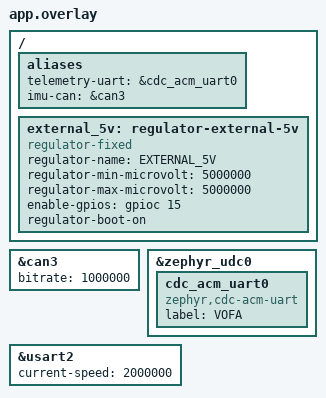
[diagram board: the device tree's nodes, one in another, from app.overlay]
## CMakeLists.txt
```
cmake_minimum_required(VERSION 3.20.0)
find_package(Zephyr REQUIRED HINTS $ENV{ZEPHYR_BASE})
project(dual_imu_bench LANGUAGES C CXX)
target_sources(app PRIVATE src/main.cpp)
```

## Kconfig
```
mainmenu "Dual-controller IMU observation bench"

config DUAL_IMU_CHASSIS_BOARD
    bool "Onboard IMU is mounted on the chassis"
    default n
    help
        Select the chassis board observation profile. The default is the
        gimbal board mounted on the large-Yaw carrier, with an external IMU
        on the pitching head. This labels mechanical frames; it does not
        fuse orientations or establish a shared inertial reference.

source "Kconfig.zephyr"
```

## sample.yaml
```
sample:
  name: SkyWalker onboard and CAN IMU with VOFA
  description: BMI088 EKF and heater together with DM-IMU-L1 on CAN3
common:
  tags: [skywalker, hardware, imu]
  platform_allow: [dm_mc02/stm32h723xx]
  build_only: true
tests:
  sample.skywalker.imu.dual: {}
  sample.skywalker.imu.chassis:
    extra_args: EXTRA_CONF_FILE=chassis.conf
```

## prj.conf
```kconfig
CONFIG_CPP=y
CONFIG_STD_CPP20=y
CONFIG_REQUIRES_FULL_LIBCPP=y
CONFIG_MAIN_STACK_SIZE=2048
CONFIG_LOG=y
CONFIG_SERIAL=y
CONFIG_UART_ASYNC_API=y
CONFIG_NOCACHE_MEMORY=y
CONFIG_PWM=y
CONFIG_SENSOR=y
CONFIG_BMI08X=y
CONFIG_SKYWALKER_LIB_COMMUNICATION=y
CONFIG_SKYWALKER_UART_TRANSPORT=y
CONFIG_SKYWALKER_LIB_VOFA=y
CONFIG_SKYWALKER_REMOTE_DR16=n
CONFIG_SKYWALKER_REFEREE=n
CONFIG_SKYWALKER_INTERBOARD=n
CONFIG_SKYWALKER_IMU=y
CONFIG_SKYWALKER_IMU_RECEIVER=y
CONFIG_SKYWALKER_IMU_BMI088=y
CONFIG_SKYWALKER_IMU_HEATER=y
CONFIG_SKYWALKER_ATTITUDE_EKF=y
CONFIG_CAN=y
CONFIG_REGULATOR=y
CONFIG_SKYWALKER_IMU_DM_RS485=n
CONFIG_SKYWALKER_IMU_DM_CAN=y
CONFIG_SKYWALKER_IMU_DM_CAN_PASSIVE=n
CONFIG_SKYWALKER_IMU_DM_CAN_SLAVE_ID=0x1
CONFIG_SKYWALKER_IMU_DM_CAN_FEEDBACK_ID=0x11
CONFIG_FPU=y
CONFIG_FPU_SHARING=y

# USB CDC telemetry; console remains on the board UART.
CONFIG_USB_DEVICE_STACK_NEXT=y
CONFIG_CDC_ACM_SERIAL_INITIALIZE_AT_BOOT=y
CONFIG_CDC_ACM_SERIAL_PRODUCT_STRING="SkyWalker Telemetry"
CONFIG_USBD_CDC_ACM_LOG_LEVEL_WRN=y
```

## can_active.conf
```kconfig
CONFIG_CAN=y
CONFIG_SKYWALKER_IMU_DM_RS485=n
CONFIG_SKYWALKER_IMU_DM_CAN=y
CONFIG_SKYWALKER_IMU_DM_CAN_PASSIVE=n
CONFIG_SKYWALKER_IMU_DM_CAN_SLAVE_ID=0x1
CONFIG_SKYWALKER_IMU_DM_CAN_FEEDBACK_ID=0x11
```

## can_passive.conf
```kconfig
CONFIG_CAN=y
CONFIG_SKYWALKER_IMU_DM_RS485=n
CONFIG_SKYWALKER_IMU_DM_CAN=y
CONFIG_SKYWALKER_IMU_DM_CAN_PASSIVE=y
CONFIG_SKYWALKER_IMU_DM_CAN_SLAVE_ID=0x1
CONFIG_SKYWALKER_IMU_DM_CAN_FEEDBACK_ID=0x11
```

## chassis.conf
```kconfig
CONFIG_DUAL_IMU_CHASSIS_BOARD=y
```

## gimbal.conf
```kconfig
CONFIG_DUAL_IMU_CHASSIS_BOARD=n
```

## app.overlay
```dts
/ {
    aliases {
        telemetry-uart = &cdc_acm_uart0;
        imu-can = &can3;
    };

    // MC02 Power_5V_EN: shared external 5 V rail, including CAN3 connector power.
    external_5v: regulator-external-5v {
        compatible = "regulator-fixed";
        regulator-name = "EXTERNAL_5V";
        regulator-min-microvolt = <5000000>;
        regulator-max-microvolt = <5000000>;
        enable-gpios = <&gpioc 15 GPIO_ACTIVE_HIGH>;
        regulator-boot-on;
    };
};

&can3 { status = "okay"; bitrate = <1000000>; };

&zephyr_udc0 {
    cdc_acm_uart0: cdc_acm_uart0 {
        compatible = "zephyr,cdc-acm-uart";
        label = "VOFA";
    };
};

// Board alias rs485-2 already maps to this remapped USART2 (PD4/PD5/PD6).
// Firmware 2.x requires read requests; no configuration commands are sent.
&usart2 {
    current-speed = <2000000>;
};
```

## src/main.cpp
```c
#include "board_config.hpp"
#include <core/attitude.hpp>
#include <core/clock.hpp>
#include <lib/vofa/vofa.h>
#include <zephyr/logging/log.h>
#include <limits>
LOG_MODULE_REGISTER(dual_imu_bench, LOG_LEVEL_INF);
namespace imu = skywalker::imu;
namespace core = skywalker::core;
namespace {
static skywalker::communication::AsyncUart::DmaBuffers external_dma __nocache;
skywalker::control::QuaternionEkf estimator(bench::estimator);
imu::Bmi088Imu onboard_source(bench::accel, bench::gyro, bench::onboard, &estimator);
imu::DmImuRs485Source external_source(bench::external_uart, external_dma, bench::external);
imu::ImuHeater heater(bench::heater);
imu::ImuReceiver onboard(onboard_source, bench::onboard_receiver, &heater);
imu::ImuReceiver external(external_source, bench::external_receiver);
core::TimeUs ageUs(const core::Stamp &stamp, core::TimeUs now) {
    return stamp.valid && now >= stamp.time_us ? now - stamp.time_us : UINT64_MAX;
}
void logObservation(const char *mount, const imu::Snapshot &s, core::TimeUs now) {
    LOG_INF(
        "mount=%s ref=%u/%u quality=%u fresh=%x quat_seq=%llu quat_us=%llu quat_age_us=%llu gyro_seq=%llu gyro_us=%llu gyro_age_us=%llu state=%u error=%d gaps=%u",
        mount, s.sample.reference.frame_id, s.sample.reference.epoch, unsigned(s.sample.attitude_quality), s.fresh_mask,
        s.sample.orientation.stamp.sequence, s.sample.orientation.stamp.time_us, ageUs(s.sample.orientation.stamp, now),
        s.sample.gyro_rad_s.stamp.sequence, s.sample.gyro_rad_s.stamp.time_us, ageUs(s.sample.gyro_rad_s.stamp, now),
        unsigned(s.state), s.diagnostics.last_error, s.diagnostics.transport_gaps);
}
void telemetryTask(void *, void *, void *) {
    static Vofa vofa{};
    const int init = vofa_init(&vofa, bench::telemetry_uart);
    LOG_INF("VOFA init=%d", init);
    int last = 0;
    core::TimeUs next_observation = 0;
    constexpr float invalid = std::numeric_limits<float>::quiet_NaN();
    for (;;) {
        const auto a = onboard.snapshot();
        const auto b = bench::use_external ? external.snapshot() : imu::Snapshot{};
        const auto now = core::monotonicTimeUs();
        if (now >= next_observation) {
            next_observation = now + 200000;
            logObservation(bench::onboard_mount, a, now);
            if (bench::use_external)
                logObservation(bench::external_mount, b, now);
        }
        const auto ae = core::euler(a.sample.orientation.value), be = core::euler(b.sample.orientation.value);
        const auto ag = a.sample.gyro_rad_s.value, bg = b.sample.gyro_rad_s.value;
        const bool aq = a.fresh_mask & imu::Orientation, bq = b.fresh_mask & imu::Orientation;
        const bool av = a.fresh_mask & imu::Gyro, bv = b.fresh_mask & imu::Gyro;
        const float values[] = {aq ? ae.roll : invalid,
                                aq ? ae.pitch : invalid,
                                aq ? ae.yaw : invalid,
                                av ? ag.x : invalid,
                                av ? ag.y : invalid,
                                av ? ag.z : invalid,
                                bq ? be.roll : invalid,
                                bq ? be.pitch : invalid,
                                bq ? be.yaw : invalid,
                                bv ? bg.x : invalid,
                                bv ? bg.y : invalid,
                                bv ? bg.z : invalid,
                                (a.fresh_mask & imu::Temperature) ? a.sample.temperature_c.value : invalid,
                                onboard.status().heater_duty,
                                float(a.fresh_mask),
                                float(b.fresh_mask)};
        static_assert(sizeof(values) / sizeof(float) <= VOFA_MAX_FLOATS);
        const int r = init == 0 ? vofa_send(&vofa, values, VOFA_MAX_FLOATS) : init;
        if (r != last) {
            if (r < 0)
                LOG_WRN("VOFA send=%d", r);
            last = r;
        }
        k_sleep(K_MSEC(10));
    }
}
}
K_THREAD_DEFINE(telemetry_thread, 4096, telemetryTask, nullptr, nullptr, nullptr, 7, K_FP_REGS, 0);
int main() {
    LOG_INF("IMU observation: onboard=%s external=%s; sensor_to_body requires calibration", bench::onboard_mount,
            bench::use_external ? bench::external_mount : "disabled");
    const int onboard_result = onboard.start();
    const int external_result = bench::use_external ? external.start() : 0;
    LOG_INF("IMU workers: onboard=%d external=%d", onboard_result, external_result);
    return onboard_result < 0 ? onboard_result : external_result;
}
```

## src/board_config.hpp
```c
#pragma once
#include <drivers/imu/bmi088_imu.hpp>
#if defined(CONFIG_SKYWALKER_IMU_DM_CAN)
#include <drivers/imu/dm_imu_can.hpp>
#else
#include <drivers/imu/dm_imu_rs485.hpp>
#endif
#include <drivers/imu/imu_heater.hpp>
#include <drivers/imu/imu_receiver.hpp>
#include <robotics/vehicle/calibration.hpp>
namespace bench {
// Frame IDs distinguish installations, epochs distinguish reference sessions.
// TODO(IMU): measure the three mounting transforms in the shared calibration.
// Acquisition remains available while imu_mounting_confirmed is false, so this
// observation bench can produce the calibration used by execution samples.
namespace calibration = skywalker::robotics::vehicle;
inline constexpr bool chassis_board = IS_ENABLED(CONFIG_DUAL_IMU_CHASSIS_BOARD);
inline constexpr bool use_external = !chassis_board;
inline constexpr const char *onboard_mount = chassis_board ? "chassis" : "large_yaw_carrier";
inline constexpr const char *external_mount = "pitching_head";
inline constexpr skywalker::imu::ImuReceiver::Config onboard_receiver{.poll_interval_us = 500, .priority = 5};
inline constexpr skywalker::imu::ImuReceiver::Config external_receiver{.poll_interval_us = 1000, .priority = 6};
inline const device *accel = DEVICE_DT_GET(DT_ALIAS(accel0));
inline const device *gyro = DEVICE_DT_GET(DT_ALIAS(gyro0));
#if !defined(CONFIG_SKYWALKER_IMU_DM_CAN)
inline const device *external_uart = DEVICE_DT_GET(DT_ALIAS(rs485_2));
#endif
inline const device *telemetry_uart = DEVICE_DT_GET(DT_ALIAS(telemetry_uart));
inline constexpr skywalker::control::QuaternionEkf::Config estimator{};
inline constexpr skywalker::imu::Bmi088Imu::Config onboard{.reference = chassis_board ? calibration::chassis_reference
                                                                                      : calibration::carrier_reference,
                                                           .sensor_to_body = chassis_board
                                                                                 ? calibration::chassis_sensor_to_body
                                                                                 : calibration::carrier_sensor_to_body,
                                                           .freshness = {20000, 20000, 20000, 200000}};
#if defined(CONFIG_SKYWALKER_IMU_DM_CAN)
inline const skywalker::imu::DmImuCanSource::Config
    external{.can = DEVICE_DT_GET(DT_ALIAS(imu_can)),
             .feedback_id = CONFIG_SKYWALKER_IMU_DM_CAN_FEEDBACK_ID,
             .slave_id = CONFIG_SKYWALKER_IMU_DM_CAN_SLAVE_ID,
             .mode = IS_ENABLED(CONFIG_SKYWALKER_IMU_DM_CAN_PASSIVE)
                         ? skywalker::imu::DmImuCanSource::Mode::RequestReply
                         : skywalker::imu::DmImuCanSource::Mode::ActiveReport,
             .reference = calibration::head_reference,
             .sensor_to_body = calibration::head_sensor_to_body};
#else
inline constexpr skywalker::imu::DmImuRs485Source::Config external{.protocol = {1, 20000},
                                                                   .reference = calibration::head_reference,
                                                                   .sensor_to_body = calibration::head_sensor_to_body,
                                                                   .device_quaternion_is_world_to_sensor = false,
                                                                   .acceleration_scale = 1,
                                                                   .angular_velocity_scale = 1,
                                                                   .response_timeout_us = 50000,
                                                                   .max_retries = 2};
#endif
inline const skywalker::imu::ImuHeater::Config heater{.pwm = PWM_DT_SPEC_GET(DT_ALIAS(imu_heater)),
                                                      .target_c = 50,
                                                      .maximum_c = 65};
}
```
